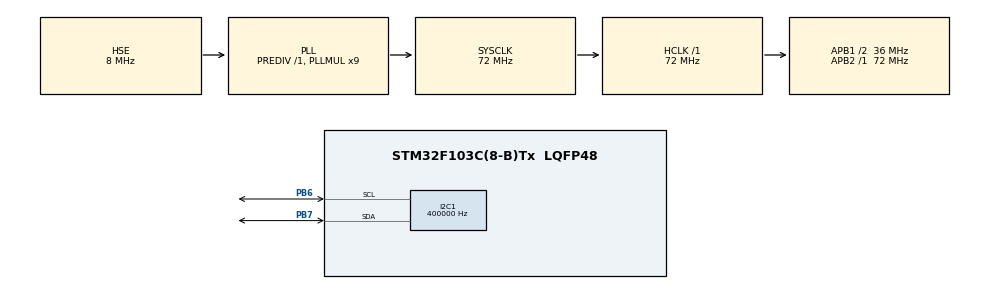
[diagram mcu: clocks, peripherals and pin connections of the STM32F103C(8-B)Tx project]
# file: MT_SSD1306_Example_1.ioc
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I2C1.ClockSpeed=400000
I2C1.I2C_Mode=I2C_Fast
Mcu.Family=STM32F1
Mcu.Name=STM32F103C(8-B)Tx
Mcu.Package=LQFP48
NVIC.I2C1_EV_IRQn=true\:0\:0\:false\:false\:true\:true\:true
NVIC.PriorityGroup=NVIC_PRIORITYGROUP_4
PA13.Mode=Serial_Wire
PA13.Signal=SYS_JTMS-SWDIO
PA14.Mode=Serial_Wire
PA14.Signal=SYS_JTCK-SWCLK
PB6.Mode=I2C
PB6.Signal=I2C1_SCL
PB7.Mode=I2C
PB7.Signal=I2C1_SDA
PD0-OSC_IN.Mode=HSE-External-Oscillator
PD0-OSC_IN.Signal=RCC_OSC_IN
PD1-OSC_OUT.Mode=HSE-External-Oscillator
PD1-OSC_OUT.Signal=RCC_OSC_OUT
ProjectManager.HeapSize=0x200
ProjectManager.StackSize=0x400
ProjectManager.TargetToolchain=EWARM V8.32
RCC.AHBFreq_Value=72000000
RCC.APB1CLKDivider=RCC_HCLK_DIV2
RCC.APB1Freq_Value=36000000
RCC.APB1TimFreq_Value=72000000
RCC.APB2Freq_Value=72000000
RCC.APB2TimFreq_Value=72000000
RCC.HCLKFreq_Value=72000000
RCC.PLLMUL=RCC_PLL_MUL9
RCC.PLLSourceVirtual=RCC_PLLSOURCE_HSE
RCC.SYSCLKFreq_VALUE=72000000
RCC.SYSCLKSource=RCC_SYSCLKSOURCE_PLLCLK
RCC.USBFreq_Value=72000000
board=custom

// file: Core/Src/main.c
/* USER CODE BEGIN Header */
/**
  ******************************************************************************
  * @file           : main.c
  * @brief          : Main program body
  ******************************************************************************
  * @attention
  *
  * <h2><center>&copy; Copyright (c) 2021 STMicroelectronics.
  * All rights reserved.</center></h2>
  *
  * This software component is licensed by ST under BSD 3-Clause license,
  * the "License"; You may not use this file except in compliance with the
  * License. You may obtain a copy of the License at:
  *                        opensource.org/licenses/BSD-3-Clause
  *
  ******************************************************************************
  */
/* USER CODE END Header */
#include "main.h"

/* USER CODE BEGIN Includes */
#include "ssd1306.h"

/* USER CODE END Includes */

I2C_HandleTypeDef hi2c1;

void SystemClock_Config(void);
static void MX_GPIO_Init(void);
static void MX_I2C1_Init(void);

int main(void)
{

  /* MCU Configuration--------------------------------------------------------*/

  /* Reset of all peripherals, Initializes the Flash interface and the Systick. */
  HAL_Init();

  /* Configure the system clock */
  SystemClock_Config();

  /* Initialize all configured peripherals */
  MX_GPIO_Init();
  MX_I2C1_Init();
  /* USER CODE BEGIN 2 */
  SSD1306_Init();
  SSD1306_ClearScreen();
  while(SSD1306_IsReady() == 0);

  /* USER CODE END 2 */

  /* Infinite loop */
  while (1)
  {

    /* USER CODE BEGIN 3 */

    for (uint8_t  i = 0; i < 8; i++)
    {
      SSD1306_DrawFilledRect(i * 16, i * 16 + 8, 16, 48);
      SSD1306_UpdateScreen();
      while(SSD1306_IsReady() == 0);

      HAL_Delay(25);
    }

    SSD1306_ClearScreen();
    while(SSD1306_IsReady() == 0);
  }
  /* USER CODE END 3 */
}

void SystemClock_Config(void)
{
  RCC_OscInitTypeDef RCC_OscInitStruct = {0};
  RCC_ClkInitTypeDef RCC_ClkInitStruct = {0};

  /** Initializes the RCC Oscillators according to the specified parameters
  * in the RCC_OscInitTypeDef structure.
  */
  RCC_OscInitStruct.OscillatorType = RCC_OSCILLATORTYPE_HSE;
  RCC_OscInitStruct.HSEState = RCC_HSE_ON;
  RCC_OscInitStruct.HSEPredivValue = RCC_HSE_PREDIV_DIV1;
  RCC_OscInitStruct.HSIState = RCC_HSI_ON;
  RCC_OscInitStruct.PLL.PLLState = RCC_PLL_ON;
  RCC_OscInitStruct.PLL.PLLSource = RCC_PLLSOURCE_HSE;
  RCC_OscInitStruct.PLL.PLLMUL = RCC_PLL_MUL9;
  if (HAL_RCC_OscConfig(&RCC_OscInitStruct) != HAL_OK)
  {
    Error_Handler();
  }
  /** Initializes the CPU, AHB and APB buses clocks
  */
  RCC_ClkInitStruct.ClockType = RCC_CLOCKTYPE_HCLK|RCC_CLOCKTYPE_SYSCLK
                              |RCC_CLOCKTYPE_PCLK1|RCC_CLOCKTYPE_PCLK2;
  RCC_ClkInitStruct.SYSCLKSource = RCC_SYSCLKSOURCE_PLLCLK;
  RCC_ClkInitStruct.AHBCLKDivider = RCC_SYSCLK_DIV1;
  RCC_ClkInitStruct.APB1CLKDivider = RCC_HCLK_DIV2;
  RCC_ClkInitStruct.APB2CLKDivider = RCC_HCLK_DIV1;

  if (HAL_RCC_ClockConfig(&RCC_ClkInitStruct, FLASH_LATENCY_2) != HAL_OK)
  {
    Error_Handler();
  }
}

static void MX_I2C1_Init(void)
{

  hi2c1.Instance = I2C1;
  hi2c1.Init.ClockSpeed = 400000;
  hi2c1.Init.DutyCycle = I2C_DUTYCYCLE_2;
  hi2c1.Init.OwnAddress1 = 0;
  hi2c1.Init.AddressingMode = I2C_ADDRESSINGMODE_7BIT;
  hi2c1.Init.DualAddressMode = I2C_DUALADDRESS_DISABLE;
  hi2c1.Init.OwnAddress2 = 0;
  hi2c1.Init.GeneralCallMode = I2C_GENERALCALL_DISABLE;
  hi2c1.Init.NoStretchMode = I2C_NOSTRETCH_DISABLE;
  if (HAL_I2C_Init(&hi2c1) != HAL_OK)
  {
    Error_Handler();
  }

}

static void MX_GPIO_Init(void)
{

  /* GPIO Ports Clock Enable */
  __HAL_RCC_GPIOD_CLK_ENABLE();
  __HAL_RCC_GPIOA_CLK_ENABLE();
  __HAL_RCC_GPIOB_CLK_ENABLE();

}

void Error_Handler(void)
{
  __disable_irq();
  while (1)
  {
  }
}

/************************ (C) COPYRIGHT STMicroelectronics *****END OF FILE****/
